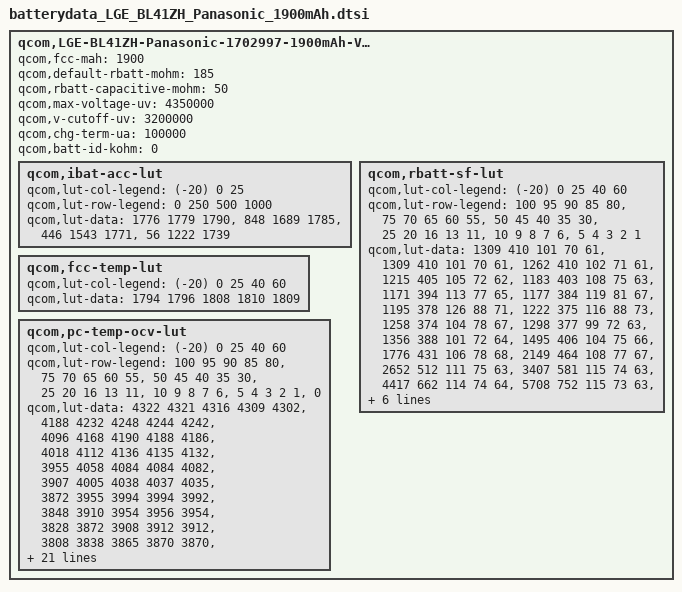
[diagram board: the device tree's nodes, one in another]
 qcom,LGE-BL41ZH-Panasonic-1702997-1900mAh-VBMS-data {
	qcom,fcc-mah = <1900>;
	qcom,default-rbatt-mohm = <185>;
	qcom,rbatt-capacitive-mohm = <50>;
	qcom,max-voltage-uv = <4350000>;
	qcom,v-cutoff-uv = <3200000>;
	qcom,chg-term-ua = <100000>;
	qcom,batt-id-kohm = <0>;

	qcom,ibat-acc-lut {
		qcom,lut-col-legend = <(-20) 0 25>;
		qcom,lut-row-legend = <0 250 500 1000>;
		qcom,lut-data = <1776 1779 1790>,
				<848 1689 1785>,
				<446 1543 1771>,
				<56 1222 1739>;
	};

	qcom,rbatt-sf-lut {
		qcom,lut-col-legend = <(-20) 0 25 40 60>;
		qcom,lut-row-legend = <100 95 90 85 80>,
				<75 70 65 60 55>,
				<50 45 40 35 30>,
				<25 20 16 13 11>,
				<10 9 8 7 6>,
				<5 4 3 2 1>;
		qcom,lut-data = <1309 410 101 70 61>,
				<1309 410 101 70 61>,
				<1262 410 102 71 61>,
				<1215 405 105 72 62>,
				<1183 403 108 75 63>,
				<1171 394 113 77 65>,
				<1177 384 119 81 67>,
				<1195 378 126 88 71>,
				<1222 375 116 88 73>,
				<1258 374 104 78 67>,
				<1298 377 99 72 63>,
				<1356 388 101 72 64>,
				<1495 406 104 75 66>,
				<1776 431 106 78 68>,
				<2149 464 108 77 67>,
				<2652 512 111 75 63>,
				<3407 581 115 74 63>,
				<4417 662 114 74 64>,
				<5708 752 115 73 63>,
				<6650 819 119 74 64>,
				<7669 864 124 77 66>,
				<8634 909 130 79 67>,
				<9598 955 138 83 68>,
				<11370 1006 148 86 69>,
				<13250 1057 149 84 67>,
				<15566 1063 141 79 64>,
				<20222 1279 138 80 68>,
				<28364 1779 147 85 73>,
				<44116 2796 166 96 80>,
				<82422 5395 332 192 160>;
	};

	qcom,fcc-temp-lut {
		qcom,lut-col-legend = <(-20) 0 25 40 60>;
		qcom,lut-data = <1794 1796 1808 1810 1809>;
	};

	qcom,pc-temp-ocv-lut {
		qcom,lut-col-legend = <(-20) 0 25 40 60>;
		qcom,lut-row-legend = <100 95 90 85 80>,
				<75 70 65 60 55>,
				<50 45 40 35 30>,
				<25 20 16 13 11>,
				<10 9 8 7 6>,
				<5 4 3 2 1>,
				<0>;
		qcom,lut-data = <4322 4321 4316 4309 4302>,
				<4188 4232 4248 4244 4242>,
				<4096 4168 4190 4188 4186>,
				<4018 4112 4136 4135 4132>,
				<3955 4058 4084 4084 4082>,
				<3907 4005 4038 4037 4035>,
				<3872 3955 3994 3994 3992>,
				<3848 3910 3954 3956 3954>,
				<3828 3872 3908 3912 3912>,
				<3808 3838 3865 3870 3870>,
				<3790 3811 3835 3838 3838>,
				<3771 3792 3813 3816 3816>,
				<3752 3776 3795 3798 3798>,
				<3731 3759 3780 3783 3782>,
				<3709 3742 3768 3768 3764>,
				<3684 3724 3752 3750 3738>,
				<3657 3706 3730 3728 3715>,
				<3628 3692 3702 3702 3690>,
				<3601 3678 3688 3685 3674>,
				<3582 3668 3680 3678 3667>,
				<3568 3660 3678 3676 3666>,
				<3554 3653 3676 3675 3665>,
				<3540 3644 3672 3672 3661>,
				<3522 3628 3667 3670 3656>,
				<3504 3612 3654 3656 3637>,
				<3482 3586 3624 3624 3597>,
				<3454 3549 3574 3572 3542>,
				<3415 3497 3506 3504 3472>,
				<3356 3421 3412 3411 3370>,
				<3252 3294 3260 3256 3220>,
				<3000 3000 3000 3000 3000>;
	};
};
